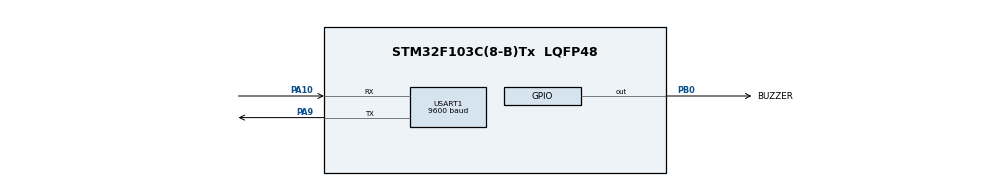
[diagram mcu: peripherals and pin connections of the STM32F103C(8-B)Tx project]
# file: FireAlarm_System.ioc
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FREERTOS.Tasks01=defaultTask,0,128,StartDefaultTask,Default,NULL,Dynamic,NULL,NULL
FREERTOS.configTOTAL_HEAP_SIZE=8192
Mcu.Family=STM32F1
Mcu.Name=STM32F103C(8-B)Tx
Mcu.Package=LQFP48
NVIC.PriorityGroup=NVIC_PRIORITYGROUP_4
NVIC.TIM4_IRQn=true\:15\:0\:false\:false\:true\:false\:false\:true\:true
NVIC.TimeBase=TIM4_IRQn
NVIC.TimeBaseIP=TIM4
PA10.Mode=Asynchronous
PA10.Signal=USART1_RX
PA9.Mode=Asynchronous
PA9.Signal=USART1_TX
PB0.GPIO_Label=BUZZER
PB0.Signal=GPIO_Output
ProjectManager.HeapSize=0x200
ProjectManager.StackSize=0x400
ProjectManager.TargetToolchain=STM32CubeIDE
RCC.APB1Freq_Value=8000000
RCC.APB2Freq_Value=8000000
USART1.BaudRate=9600
USART1.VirtualMode=VM_ASYNC
VP_FREERTOS_VS_CMSIS_V1.Mode=CMSIS_V1
VP_SYS_VS_ND.Mode=No_Debug
VP_SYS_VS_tim4.Mode=TIM4
board=custom

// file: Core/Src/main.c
/* USER CODE BEGIN Header */
/**
  ******************************************************************************
  * @file           : main.c
  * @brief          : Main program body
  ******************************************************************************
  * @attention
  *
  * Copyright (c) 2026 STMicroelectronics.
  * All rights reserved.
  *
  * This software is licensed under terms that can be found in the LICENSE file
  * in the root directory of this software component.
  * If no LICENSE file comes with this software, it is provided AS-IS.
  *
  ******************************************************************************
  */
/* USER CODE END Header */
#include "main.h"
#include "cmsis_os.h"

UART_HandleTypeDef huart1;

osThreadId defaultTaskHandle;

void SystemClock_Config(void);
static void MX_GPIO_Init(void);
static void MX_USART1_UART_Init(void);
void StartDefaultTask(void const * argument);

int main(void)
{

  /* MCU Configuration--------------------------------------------------------*/

  /* Reset of all peripherals, Initializes the Flash interface and the Systick. */
  HAL_Init();

  /* Configure the system clock */
  SystemClock_Config();

  /* Initialize all configured peripherals */
  MX_GPIO_Init();
  MX_USART1_UART_Init();
  /* USER CODE BEGIN 2 */
  vStartFreeRTOSTasks();
  /* USER CODE END 2 */

  /* Create the thread(s) */
  /* definition and creation of defaultTask */
  osThreadDef(defaultTask, StartDefaultTask, osPriorityNormal, 0, 128);
  defaultTaskHandle = osThreadCreate(osThread(defaultTask), NULL);

  /* Start scheduler */
  osKernelStart();

  /* We should never get here as control is now taken by the scheduler */

  /* Infinite loop */
  while (1)
  {

  }
}

void SystemClock_Config(void)
{
  RCC_OscInitTypeDef RCC_OscInitStruct = {0};
  RCC_ClkInitTypeDef RCC_ClkInitStruct = {0};

  /** Initializes the RCC Oscillators according to the specified parameters
  * in the RCC_OscInitTypeDef structure.
  */
  RCC_OscInitStruct.OscillatorType = RCC_OSCILLATORTYPE_HSI;
  RCC_OscInitStruct.HSIState = RCC_HSI_ON;
  RCC_OscInitStruct.HSICalibrationValue = RCC_HSICALIBRATION_DEFAULT;
  RCC_OscInitStruct.PLL.PLLState = RCC_PLL_NONE;
  if (HAL_RCC_OscConfig(&RCC_OscInitStruct) != HAL_OK)
  {
    Error_Handler();
  }

  /** Initializes the CPU, AHB and APB buses clocks
  */
  RCC_ClkInitStruct.ClockType = RCC_CLOCKTYPE_HCLK|RCC_CLOCKTYPE_SYSCLK
                              |RCC_CLOCKTYPE_PCLK1|RCC_CLOCKTYPE_PCLK2;
  RCC_ClkInitStruct.SYSCLKSource = RCC_SYSCLKSOURCE_HSI;
  RCC_ClkInitStruct.AHBCLKDivider = RCC_SYSCLK_DIV1;
  RCC_ClkInitStruct.APB1CLKDivider = RCC_HCLK_DIV1;
  RCC_ClkInitStruct.APB2CLKDivider = RCC_HCLK_DIV1;

  if (HAL_RCC_ClockConfig(&RCC_ClkInitStruct, FLASH_LATENCY_0) != HAL_OK)
  {
    Error_Handler();
  }
}

static void MX_USART1_UART_Init(void)
{

  huart1.Instance = USART1;
  huart1.Init.BaudRate = 9600;
  huart1.Init.WordLength = UART_WORDLENGTH_8B;
  huart1.Init.StopBits = UART_STOPBITS_1;
  huart1.Init.Parity = UART_PARITY_NONE;
  huart1.Init.Mode = UART_MODE_TX_RX;
  huart1.Init.HwFlowCtl = UART_HWCONTROL_NONE;
  huart1.Init.OverSampling = UART_OVERSAMPLING_16;
  if (HAL_UART_Init(&huart1) != HAL_OK)
  {
    Error_Handler();
  }

}

static void MX_GPIO_Init(void)
{
  GPIO_InitTypeDef GPIO_InitStruct = {0};

  /* GPIO Ports Clock Enable */
  __HAL_RCC_GPIOB_CLK_ENABLE();
  __HAL_RCC_GPIOA_CLK_ENABLE();

  /*Configure GPIO pin Output Level */
  HAL_GPIO_WritePin(BUZZER_GPIO_Port, BUZZER_Pin, GPIO_PIN_RESET);

  /*Configure GPIO pin : BUZZER_Pin */
  GPIO_InitStruct.Pin = BUZZER_Pin;
  GPIO_InitStruct.Mode = GPIO_MODE_OUTPUT_PP;
  GPIO_InitStruct.Pull = GPIO_NOPULL;
  GPIO_InitStruct.Speed = GPIO_SPEED_FREQ_LOW;
  HAL_GPIO_Init(BUZZER_GPIO_Port, &GPIO_InitStruct);

}

void StartDefaultTask(void const * argument)
{
  for(;;)
  {
    osDelay(1);
  }
}

void HAL_TIM_PeriodElapsedCallback(TIM_HandleTypeDef *htim)
{
  if (htim->Instance == TIM4)
  {
    HAL_IncTick();
  }
}

void Error_Handler(void)
{
  __disable_irq();
  while (1)
  {
  }
}

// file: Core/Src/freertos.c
/* USER CODE BEGIN Header */
/**
  ******************************************************************************
  * File Name          : freertos.c
  * Description        : Code for freertos applications
  ******************************************************************************
  * @attention
  *
  * Copyright (c) 2026 STMicroelectronics.
  * All rights reserved.
  *
  * This software is licensed under terms that can be found in the LICENSE file
  * in the root directory of this software component.
  * If no LICENSE file comes with this software, it is provided AS-IS.
  *
  ******************************************************************************
  */
/* USER CODE END Header */

#include "FreeRTOS.h"
#include "task.h"
#include "main.h"

/* USER CODE BEGIN Includes */
#include "queue.h"
#include "semphr.h"
/* USER CODE END Includes */

/* USER CODE BEGIN Variables */
// Semaphore và Queue
SemaphoreHandle_t xSem_FireAlarm;
QueueHandle_t xQueue_ESP;

// Handle các Task
TaskHandle_t xTask_Sensor_Handle;
TaskHandle_t xTask_Battery_LCD_Handle;
TaskHandle_t xTask_FireAlarm_Handle;
TaskHandle_t xTask_ESP_Handle;

/* USER CODE END Variables */

/* USER CODE BEGIN FunctionPrototypes */

void vTask_Sensor(void *pvParameters);
void vTask_Battery_LCD(void *pvParameters);
void vTask_FireAlarm(void *pvParameters);
void vTask_ESP(void *pvParameters);
/* USER CODE END FunctionPrototypes */

/* GetIdleTaskMemory prototype (linked to static allocation support) */
void vApplicationGetIdleTaskMemory( StaticTask_t **ppxIdleTaskTCBBuffer, StackType_t **ppxIdleTaskStackBuffer, uint32_t *pulIdleTaskStackSize );

/* USER CODE BEGIN GET_IDLE_TASK_MEMORY */
static StaticTask_t xIdleTaskTCBBuffer;
static StackType_t xIdleStack[configMINIMAL_STACK_SIZE];

void vApplicationGetIdleTaskMemory( StaticTask_t **ppxIdleTaskTCBBuffer, StackType_t **ppxIdleTaskStackBuffer, uint32_t *pulIdleTaskStackSize )
{
  *ppxIdleTaskTCBBuffer = &xIdleTaskTCBBuffer;
  *ppxIdleTaskStackBuffer = &xIdleStack[0];
  *pulIdleTaskStackSize = configMINIMAL_STACK_SIZE;
  /* place for user code */
}
/* USER CODE END GET_IDLE_TASK_MEMORY */

/* USER CODE BEGIN Application */

void vStartFreeRTOSTasks(void)
{
    xSem_FireAlarm = xSemaphoreCreateBinary();
    xQueue_ESP = xQueueCreate(5, sizeof(ESP_Message_t));

    xTaskCreate(vTask_Sensor,       "Task_Sensor",      128, NULL, 3, &xTask_Sensor_Handle);
    xTaskCreate(vTask_Battery_LCD,  "Task_Battery_LCD", 128, NULL, 1, &xTask_Battery_LCD_Handle);
    xTaskCreate(vTask_FireAlarm,    "Task_FireAlarm",   128, NULL, 4, &xTask_FireAlarm_Handle);
    xTaskCreate(vTask_ESP,          "Task_ESP",         128, NULL, 1, &xTask_ESP_Handle);
}

// TASK C: Task_FireAlarm - NHIỆM VỤ CỦA ĐOÀN TRỌNG THÁI
void vTask_FireAlarm(void *pvParameters)
{
    for(;;)
    {
        if(xSemaphoreTake(xSem_FireAlarm, portMAX_DELAY) == pdTRUE)
        {
            // Kích hoạt còi
            HAL_GPIO_WritePin(BUZZER_GPIO_Port, BUZZER_Pin, GPIO_PIN_SET);

            // Gửi vào Queue để Task_ESP gửi lên Telegram
            ESP_Message_t msg = FIRE_ALARM;
            xQueueSend(xQueue_ESP, &msg, 0);
        }

        vTaskDelay(pdMS_TO_TICKS(fire_alarm_delay));
    }
}

void vTask_Sensor(void *pvParameters)
{
    for(;;)
    {
        // Giả lập phát hiện cháy mỗi 5 giây
        xSemaphoreGive(xSem_FireAlarm);
        vTaskDelay(pdMS_TO_TICKS(5000));
    }
}
void vTask_Battery_LCD(void *pvParameters) { for(;;) { vTaskDelay(pdMS_TO_TICKS(battery_lcd_delay)); } }
void vTask_ESP(void *pvParameters)         { for(;;) { vTaskDelay(pdMS_TO_TICKS(esp_delay)); } }

/* USER CODE END Application */
